# ATtiny45 device description
Architecture: AVR8; Family: tinyAVR
Registers are 8-bit, access not given, no defined reset value unless marked. A register's access mark holds for its fields unless they carry their own. Offsets are from the block's base; [hi:lo] are bit positions.

## FUSE — Fuses
Instances: FUSE 0 in fuses
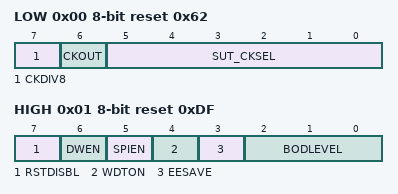
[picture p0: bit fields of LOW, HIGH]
0x00 LOW reset 0x62
  [7] CKDIV8 — Divide clock by 8 internally
  [6] CKOUT — Clock output on PORTB4
  [5:0] SUT_CKSEL — Select Clock source
    0=EXTCLK_6CK_14CK_0MS (Ext. Clock; Start-up time PWRDWN/RESET: 6 CK/14 CK + 0 ms); 16=EXTCLK_6CK_14CK_4MS1 (Ext. Clock; Start-up time PWRDWN/RESET: 6 CK/14 CK + 4.1 ms); 32=EXTCLK_6CK_14CK_65MS (Ext. Clock; Start-up time PWRDWN/RESET: 6 CK/14 CK + 65 ms); 1=PLLCLK_1KCK_14CK_4MS (PLL Clock; Start-up time PWRDWN/RESET: 1K CK/14 CK + 4 ms); 17=PLLCLK_16KCK_14CK_4MS (PLL Clock; Start-up time PWRDWN/RESET: 16K CK/14 CK + 4 ms); 33=PLLCLK_1KCK_14CK_64MS (PLL Clock; Start-up time PWRDWN/RESET: 1K CK/14 CK + 64 ms); 49=PLLCLK_16KCK_14CK_64MS (PLL Clock; Start-up time PWRDWN/RESET: 16K CK/14 CK + 64 ms); 2=INTRCOSC_8MHZ_6CK_14CK_0MS (Int. RC Osc. 8 MHz; Start-up time PWRDWN/RESET: 6 CK/14 CK + 0 ms); 18=INTRCOSC_8MHZ_6CK_14CK_4MS (Int. RC Osc. 8 MHz; Start-up time PWRDWN/RESET: 6 CK/14 CK + 4 ms); 34=INTRCOSC_8MHZ_6CK_14CK_64MS (Int. RC Osc. 8 MHz; Start-up time PWRDWN/RESET: 6 CK/14 CK + 64 ms); 3=INTRCOSC_4MHZ_6CK_14CK_64MS (ATtiny15 Comp: Int. RC Osc. 6.4 MHz; Start-up time PWRDWN/RESET: 6 CK/14 CK + 64 ms); 19=INTRCOSC_4MHZ_6CK_14CK_64MS (ATtiny15 Comp: Int. RC Osc. 6.4 MHz; Start-up time PWRDWN/RESET: 6 CK/14 CK + 64 ms); 35=INTRCOSC_4MHZ_6CK_14CK_4MS (ATtiny15 Comp: Int. RC Osc. 6.4 MHz; Start-up time PWRDWN/RESET: 6 CK/14 CK + 4 ms); 51=INTRCOSC_4MHZ_1CK_14CK_0MS (ATtiny15 Comp: Int. RC Osc. 6.4 MHz; Start-up time PWRDWN/RESET: 1 CK/14 CK + 0 ms); 4=WDOSC_128KHZ_6CK_14CK_0MS (WD. Osc. 128 kHz; Start-up time PWRDWN/RESET: 6 CK/14 CK + 0 ms); 20=WDOSC_128KHZ_6CK_14CK_4MS (WD. Osc. 128 kHz; Start-up time PWRDWN/RESET: 6 CK/14 CK + 4 ms); 36=WDOSC_128KHZ_6CK_14CK_64MS (WD. Osc. 128 kHz; Start-up time PWRDWN/RESET: 6 CK/14 CK + 64 ms); 6=EXTLOFXTAL_1KCK_14CK_0MS (Ext. Low-Freq. Crystal; Start-up time PWRDWN/RESET: 1K CK/14 CK + 0 ms); 22=EXTLOFXTAL_1KCK_14CK_4MS (Ext. Low-Freq. Crystal; Start-up time PWRDWN/RESET: 1K CK/14 CK + 4 ms); 38=EXTLOFXTAL_32KCK_14CK_64MS (Ext. Low-Freq. Crystal; Start-up time PWRDWN/RESET: 32K CK/14 CK + 64 ms); 8=EXTXOSC_0MHZ4_0MHZ9_258CK_14CK_4MS1 (Ext. Crystal Osc. 0.4-0.9 MHz; Start-up time PWRDWN/RESET: 258 CK/14 CK + 4.1 ms); 24=EXTXOSC_0MHZ4_0MHZ9_258CK_14CK_65MS (Ext. Crystal Osc. 0.4-0.9 MHz; Start-up time PWRDWN/RESET: 258 CK/14 CK + 65 ms); 40=EXTXOSC_0MHZ4_0MHZ9_1KCK_14CK_0MS (Ext. Crystal Osc. 0.4-0.9 MHz; Start-up time PWRDWN/RESET: 1K CK /14 CK + 0 ms); 56=EXTXOSC_0MHZ4_0MHZ9_1KCK_14CK_4MS1 (Ext. Crystal Osc. 0.4-0.9 MHz; Start-up time PWRDWN/RESET: 1K CK /14 CK + 4.1 ms); 9=EXTXOSC_0MHZ4_0MHZ9_1KCK_14CK_65MS (Ext. Crystal Osc. 0.4-0.9 MHz; Start-up time PWRDWN/RESET: 1K CK /14 CK + 65 ms); 25=EXTXOSC_0MHZ4_0MHZ9_16KCK_14CK_0MS (Ext. Crystal Osc. 0.4-0.9 MHz; Start-up time PWRDWN/RESET: 16K CK/14 CK + 0 ms); 41=EXTXOSC_0MHZ4_0MHZ9_16KCK_14CK_4MS1 (Ext. Crystal Osc. 0.4-0.9 MHz; Start-up time PWRDWN/RESET: 16K CK/14 CK + 4.1 ms); 57=EXTXOSC_0MHZ4_0MHZ9_16KCK_14CK_65MS (Ext. Crystal Osc. 0.4-0.9 MHz; Start-up time PWRDWN/RESET: 16K CK/14 CK + 65 ms); 10=EXTXOSC_0MHZ9_3MHZ_258CK_14CK_4MS1 (Ext. Crystal Osc. 0.9-3.0 MHz; Start-up time PWRDWN/RESET: 258 CK/14 CK + 4.1 ms); 26=EXTXOSC_0MHZ9_3MHZ_258CK_14CK_65MS (Ext. Crystal Osc. 0.9-3.0 MHz; Start-up time PWRDWN/RESET: 258 CK/14 CK + 65 ms); 42=EXTXOSC_0MHZ9_3MHZ_1KCK_14CK_0MS (Ext. Crystal Osc. 0.9-3.0 MHz; Start-up time PWRDWN/RESET: 1K CK /14 CK + 0 ms); 58=EXTXOSC_0MHZ9_3MHZ_1KCK_14CK_4MS1 (Ext. Crystal Osc. 0.9-3.0 MHz; Start-up time PWRDWN/RESET: 1K CK /14 CK + 4.1 ms); 11=EXTXOSC_0MHZ9_3MHZ_1KCK_14CK_65MS (Ext. Crystal Osc. 0.9-3.0 MHz; Start-up time PWRDWN/RESET: 1K CK /14 CK + 65 ms); 27=EXTXOSC_0MHZ9_3MHZ_16KCK_14CK_0MS (Ext. Crystal Osc. 0.9-3.0 MHz; Start-up time PWRDWN/RESET: 16K CK/14 CK + 0 ms); 43=EXTXOSC_0MHZ9_3MHZ_16KCK_14CK_4MS1 (Ext. Crystal Osc. 0.9-3.0 MHz; Start-up time PWRDWN/RESET: 16K CK/14 CK + 4.1 ms); 59=EXTXOSC_0MHZ9_3MHZ_16KCK_14CK_65MS (Ext. Crystal Osc. 0.9-3.0 MHz; Start-up time PWRDWN/RESET: 16K CK/14 CK + 65 ms); 12=EXTXOSC_3MHZ_8MHZ_258CK_14CK_4MS1 (Ext. Crystal Osc. 3.0-8.0 MHz; Start-up time PWRDWN/RESET: 258 CK/14 CK + 4.1 ms); 28=EXTXOSC_3MHZ_8MHZ_258CK_14CK_65MS (Ext. Crystal Osc. 3.0-8.0 MHz; Start-up time PWRDWN/RESET: 258 CK/14 CK + 65 ms); 44=EXTXOSC_3MHZ_8MHZ_1KCK_14CK_0MS (Ext. Crystal Osc. 3.0-8.0 MHz; Start-up time PWRDWN/RESET: 1K CK /14 CK + 0 ms); 60=EXTXOSC_3MHZ_8MHZ_1KCK_14CK_4MS1 (Ext. Crystal Osc. 3.0-8.0 MHz; Start-up time PWRDWN/RESET: 1K CK /14 CK + 4.1 ms); 13=EXTXOSC_3MHZ_8MHZ_1KCK_14CK_65MS (Ext. Crystal Osc. 3.0-8.0 MHz; Start-up time PWRDWN/RESET: 1K CK /14 CK + 65 ms); 29=EXTXOSC_3MHZ_8MHZ_16KCK_14CK_0MS (Ext. Crystal Osc. 3.0-8.0 MHz; Start-up time PWRDWN/RESET: 16K CK/14 CK + 0 ms); 45=EXTXOSC_3MHZ_8MHZ_16KCK_14CK_4MS1 (Ext. Crystal Osc. 3.0-8.0 MHz; Start-up time PWRDWN/RESET: 16K CK/14 CK + 4.1 ms); 61=EXTXOSC_3MHZ_8MHZ_16KCK_14CK_65MS (Ext. Crystal Osc. 3.0-8.0 MHz; Start-up time PWRDWN/RESET: 16K CK/14 CK + 65 ms); 14=EXTXOSC_8MHZ_XX_258CK_14CK_4MS1 (Ext. Crystal Osc. 8.0- MHz; Start-up time PWRDWN/RESET: 258 CK/14 CK + 4.1 ms); 30=EXTXOSC_8MHZ_XX_258CK_14CK_65MS (Ext. Crystal Osc. 8.0- MHz; Start-up time PWRDWN/RESET: 258 CK/14 CK + 65 ms); 46=EXTXOSC_8MHZ_XX_1KCK_14CK_0MS (Ext. Crystal Osc. 8.0- MHz; Start-up time PWRDWN/RESET: 1K CK /14 CK + 0 ms); 62=EXTXOSC_8MHZ_XX_1KCK_14CK_4MS1 (Ext. Crystal Osc. 8.0- MHz; Start-up time PWRDWN/RESET: 1K CK /14 CK + 4.1 ms); 15=EXTXOSC_8MHZ_XX_1KCK_14CK_65MS (Ext. Crystal Osc. 8.0- MHz; Start-up time PWRDWN/RESET: 1K CK /14 CK + 65 ms); 31=EXTXOSC_8MHZ_XX_16KCK_14CK_0MS (Ext. Crystal Osc. 8.0- MHz; Start-up time PWRDWN/RESET: 16K CK/14 CK + 0 ms); 47=EXTXOSC_8MHZ_XX_16KCK_14CK_4MS1 (Ext. Crystal Osc. 8.0- MHz; Start-up time PWRDWN/RESET: 16K CK/14 CK + 4.1 ms); 63=EXTXOSC_8MHZ_XX_16KCK_14CK_65MS (Ext. Crystal Osc. 8.0- MHz; Start-up time PWRDWN/RESET: 16K CK/14 CK + 65 ms)
0x01 HIGH reset 0xDF
  [7] RSTDISBL — Reset Disabled (Enable PB5 as i/o pin)
  [6] DWEN — Debug Wire enable
  [5] SPIEN — Serial program downloading (SPI) enabled
  [4] WDTON — Watch-dog Timer always on
  [3] EESAVE — Preserve EEPROM through the Chip Erase cycle
  [2:0] BODLEVEL — Brown-out Detector trigger level
    7=DISABLED (Brown-out detection disabled); 6=1V8 (Brown-out detection at VCC=1.8 V); 5=2V7 (Brown-out detection at VCC=2.7 V); 4=4V3 (Brown-out detection at VCC=4.3 V)
0x02 EXTENDED reset 0xFF
  [0] SELFPRGEN — Self Programming enable
